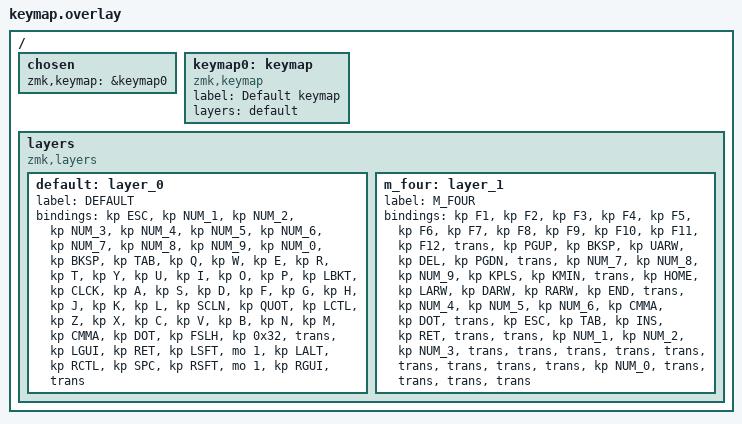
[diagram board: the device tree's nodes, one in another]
#include <dt-bindings/zmk/keys.h>
#include <behaviors.dtsi>

/ {
	chosen {
		zmk,keymap = &keymap0;
	};

	keymap0: keymap {
		compatible = "zmk,keymap";
		label ="Default keymap";
		layers = <&default>;
	};

	layers {
		compatible = "zmk,layers";

		default: layer_0 {
			label = "DEFAULT";
			bindings = <
	&kp ESC  &kp NUM_1 &kp NUM_2 &kp NUM_3 &kp NUM_4 &kp NUM_5 
                                                                &kp NUM_6 &kp NUM_7 &kp NUM_8 &kp NUM_9 &kp NUM_0 &kp BKSP
	&kp TAB  &kp Q &kp W &kp E &kp R &kp T 
                                                                &kp Y &kp U &kp I &kp O &kp P &kp LBKT
	&kp CLCK  &kp A &kp S &kp D &kp F &kp G 
                                                                &kp H &kp J &kp K &kp L &kp SCLN &kp QUOT
	&kp LCTL  &kp Z &kp X &kp C &kp V &kp B 
                                                                &kp N &kp M &kp CMMA &kp DOT &kp FSLH &kp 0x32
	&trans &kp LGUI &kp RET &kp LSFT &mo 1 &kp LALT 
                                                                &kp RCTL &kp SPC &kp RSFT &mo 1 &kp RGUI &trans
/*	&trans &kp RET &kp LGUI &kp LSFT &kp 0x64 &kp LALT 
                                                                &kp RCTL &kp SPC &kp RSFT &kp RGUI &kp RALT &trans */
			>;
		};
		m_four: layer_1 {
			label = "M_FOUR";
			bindings = <
	&kp F1  &kp F2 &kp F3 &kp F4 &kp F5 &kp F6 
                                                                &kp F7 &kp F8 &kp F9 &kp F10 &kp F11 &kp F12
	&trans  &kp PGUP &kp BKSP &kp UARW &kp DEL &kp PGDN 
                                                                &trans &kp NUM_7 &kp NUM_8 &kp NUM_9 &kp KPLS &kp KMIN
	&trans  &kp HOME &kp LARW &kp DARW &kp RARW &kp END 
                                                                &trans &kp NUM_4 &kp NUM_5 &kp NUM_6 &kp CMMA &kp DOT
	&trans  &kp ESC &kp TAB &kp INS &kp RET &trans 
                                                                &trans &kp NUM_1 &kp NUM_2 &kp NUM_3 &trans &trans
	&trans &trans &trans &trans &trans &trans 
                                                                &trans &kp NUM_0 &trans &trans &trans &trans
			>;
		};
	};
};
